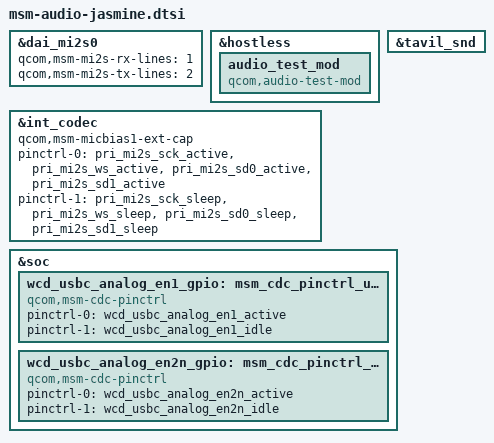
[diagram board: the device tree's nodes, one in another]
&dai_mi2s0 {
	qcom,msm-mi2s-rx-lines = <1>;
	qcom,msm-mi2s-tx-lines = <2>;
};

&hostless {
	audio_test_mod {
		compatible = "qcom,audio-test-mod";
	};
};

&tavil_snd {
	/delete-property/ qcom,usbc-analog-en1_gpio;
	/delete-property/ qcom,usbc-analog-en2_n_gpio;
};

&int_codec {
	qcom,msm-micbias1-ext-cap;
	/delete-property/ qcom,msm-micbias2-ext-cap;
	/delete-property/ qcom,us-euro-gpios;
	pinctrl-names = "pri_i2s_active", "pri_i2s_sleep";
	pinctrl-0 = <&pri_mi2s_sck_active &pri_mi2s_ws_active 
			&pri_mi2s_sd0_active &pri_mi2s_sd1_active>;
	pinctrl-1 = <&pri_mi2s_sck_sleep &pri_mi2s_ws_sleep 
			&pri_mi2s_sd0_sleep &pri_mi2s_sd1_sleep>;
};

&soc {
	wcd_usbc_analog_en1_gpio: msm_cdc_pinctrl_usbc_audio_en1 {
		compatible = "qcom,msm-cdc-pinctrl";
		pinctrl-names = "aud_active", "aud_sleep";
		pinctrl-0 = <&wcd_usbc_analog_en1_active>;
		pinctrl-1 = <&wcd_usbc_analog_en1_idle>;
	};

	wcd_usbc_analog_en2n_gpio: msm_cdc_pinctrl_usbc_audio_en2 {
		compatible = "qcom,msm-cdc-pinctrl";
		pinctrl-names = "aud_active", "aud_sleep";
		pinctrl-0 = <&wcd_usbc_analog_en2n_active>;
		pinctrl-1 = <&wcd_usbc_analog_en2n_idle>;
	};
};
